# USB2PHY register map
Vendor: Texas Instruments
Peripheral module from a debugger description file (folder omap5430_ES2_PUBLIC).
Registers are 32-bit, access per field, reset 0x0 unless marked. A register's access mark holds for its fields unless they carry their own. Offsets are as the file gives them; lines under a group give offsets from that group; [hi:lo] are bit positions; {n}, {i} and the like mark numbered series; 'fields as' and 'values as' point back to an identical list; <NAME> marks a mode.

## USB2PHY
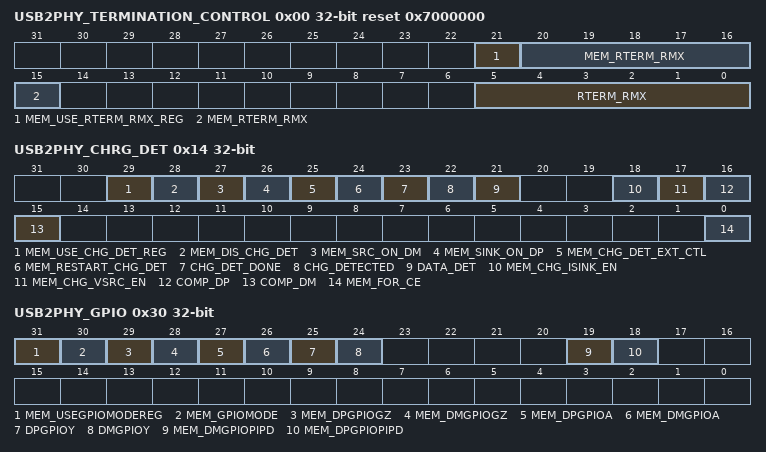
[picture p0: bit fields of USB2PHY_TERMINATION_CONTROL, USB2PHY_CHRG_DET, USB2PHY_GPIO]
0x00 USB2PHY_TERMINATION_CONTROL reset 0x7000000 — Contains bits related to control of terminations in USB2PHY
  [21] MEM_USE_RTERM_RMX_REG rw — Override termination resistor trim code with MEM_RTERM_RMX bitfield value
  [20:15] MEM_RTERM_RMX rw — The value written to this field is used as termination resistor trim code if bit [21] MEM_USE_RTERM_RMX_REG is set to 1
  [5:0] RTERM_RMX ro — Returns the current value of RTERM_RMX
0x14 USB2PHY_CHRG_DET — This is the charger detect register. This register is not used in the dead battery case.
  [29] MEM_USE_CHG_DET_REG rw — Use bits 28:24 and 18:17 from this register.
  [28] MEM_DIS_CHG_DET rw — When read, returns current value of charger detect input. When MEM_USE_CHG_DET_REG = 1, the value written to this field overrides the corresponding charger detect input.
  [27] MEM_SRC_ON_DM rw — When read, returns current value of charger detect input. When MEM_USE_CHG_DET_REG = 1, the value written to this field overrides the corresponding charger detect input.
  [26] MEM_SINK_ON_DP rw — When read, returns current value of charger detect input. When MEM_USE_CHG_DET_REG = 1, the value written to this field overrides the corresponding charger detect input.
  [25] MEM_CHG_DET_EXT_CTL rw — When read, returns current value of charger detect input. When MEM_USE_CHG_DET_REG = 1, the value written to this fileld overrides the corresponding charger detect input.
  [24] MEM_RESTART_CHG_DET rw — Restart the charger detection protocol when this bit is set from 0 to 1
  [23] CHG_DET_DONE ro — Charger detect protocol has completed
  [22] CHG_DETECTED ro — Reflects charger-enable (CE) output pin
  [21] DATA_DET ro — Output of the data detect comparator
  [18] MEM_CHG_ISINK_EN rw — When read, returns current value of charger detect input. When MEM_USE_CHG_DET_REG = 1, the value written to this field overrides the corresponding charger detect input.
  [17] MEM_CHG_VSRC_EN rw — When read, returns current value of charger detect input. When MEM_USE_CHG_DET_REG = 1, the value written to this field overrides the corresponding charger detect input.
  [16] COMP_DP ro — Comparator on the DP line value
  [15] COMP_DM ro — Comparator on the DM line value
  [0] MEM_FOR_CE rw — Force output pin CE = 1, when this bit is set to 1.
0x30 USB2PHY_GPIO — GPIO mode configurations and read-only info fields
  [31] MEM_USEGPIOMODEREG rw — When set to 1, use bits 30:24 from this register instead of primary inputs.
  [30] MEM_GPIOMODE rw — Overrides the GPIO MODE primary input
  [29] MEM_DPGPIOGZ rw — Overrides the DP GPIO GZ primary input
  [28] MEM_DMGPIOGZ rw — Overrides the DM GPIO GZ primary input
  [27] MEM_DPGPIOA rw — Overrides the DP GPIO A primary input
  [26] MEM_DMGPIOA rw — Overrides the DM GPIO A primary input
  [25] DPGPIOY ro — DP GPIO Y output value status
  [24] DMGPIOY ro — DM GPIO Y output value status
  [19] MEM_DMGPIOPIPD rw — GPIO mode DM pulldown enabled. Overrides the corresponding primary input.
  [18] MEM_DPGPIOPIPD rw — GPIO mode DP pulldown enabled. Overrides the corresponding primary input.
0x48 USB2PHY_AD_INTERFACE_REG3 — AD interface register 3
  [17:10] MEM_SPARE_IN_LDO rw — This bit field can be used to compensate for external Common Mode Filter (CMF) or series switch resistance. Returns 0x0 on read, if VDDLDO is off. Example: If a CMF has series resistance of 4 ohms, that can be compensated by lower the output impedance of the driver by 4 ohms (0x4). It is not recommended to use external components having more than 4-ohm series resistance on DP/DM path. If higher value of series resistance is used, PHY can only compensate that partially by using this option.
    {v}={v} ohms reduction in HS termination (v=0..4)
0x50 USB2PHY_ANA_CONFIG2 rw — Used to configure and debug the analog blocks
  [19:15] MEM_FSRX_TEST — Following are the bit setting to improve HS eye diagram. These options should be used with higher value of external series resistance on DP/DM.bits [17:15] = 0x0: Default swing enum=Default . bits [17:15] = 0x3: 15-mV differential swing increase enum=15 mV .
0x78 USB2PHY_CEGPIO_REG reset 0x2710000 — This register contains bits for configuring functionality for CE pad.
  [5:0] MEM_CE_SELECT rw — CE pin output mode:0x8 - 0xF: Reserved . 0x10 - 0x28: Debug options .
    0=Charger detected; 1=GPIO mode; 2=Suspendm; 3=!Suspendm; 4=Bus_reset; 5=!Bus_reset; 6=Suspendm + Bus_reset; 7=!(Suspendm + Bus_reset)
